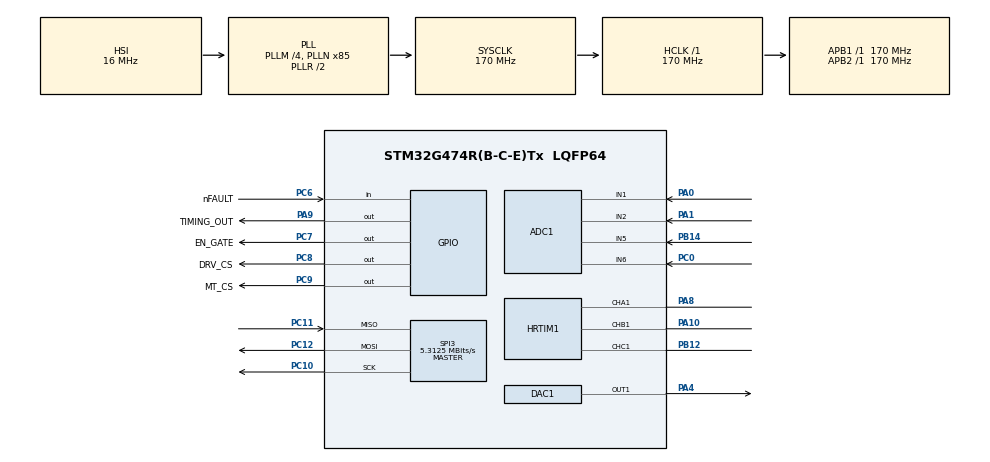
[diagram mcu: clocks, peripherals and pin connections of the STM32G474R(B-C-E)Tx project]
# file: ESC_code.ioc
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ADC1.Channel-0\#ChannelRegularConversion=ADC_CHANNEL_1
ADC1.Channel-1\#ChannelRegularConversion=ADC_CHANNEL_2
ADC1.Channel-2\#ChannelRegularConversion=ADC_CHANNEL_5
ADC1.Channel-3\#ChannelRegularConversion=ADC_CHANNEL_6
ADC1.DMAContinuousRequests=ENABLE
ADC1.ExternalTrigConv=ADC_EXTERNALTRIG_HRTIM_TRG1
ADC1.NbrOfConversion=4
ADC1.NbrOfConversionFlag=1
ADC1.OffsetNumber-0\#ChannelRegularConversion=ADC_OFFSET_NONE
ADC1.OffsetNumber-1\#ChannelRegularConversion=ADC_OFFSET_NONE
ADC1.OffsetNumber-2\#ChannelRegularConversion=ADC_OFFSET_NONE
ADC1.OffsetNumber-3\#ChannelRegularConversion=ADC_OFFSET_NONE
ADC1.Rank-0\#ChannelRegularConversion=1
ADC1.Rank-1\#ChannelRegularConversion=2
ADC1.Rank-2\#ChannelRegularConversion=3
ADC1.Rank-3\#ChannelRegularConversion=4
ADC1.SamplingTime-0\#ChannelRegularConversion=ADC_SAMPLETIME_24CYCLES_5
ADC1.SamplingTime-1\#ChannelRegularConversion=ADC_SAMPLETIME_24CYCLES_5
ADC1.SamplingTime-2\#ChannelRegularConversion=ADC_SAMPLETIME_24CYCLES_5
ADC1.SamplingTime-3\#ChannelRegularConversion=ADC_SAMPLETIME_47CYCLES_5
ADC1.master=1
Dma.ADC1.0.Direction=DMA_PERIPH_TO_MEMORY
Dma.ADC1.0.EventEnable=DISABLE
Dma.ADC1.0.Instance=DMA1_Channel1
Dma.ADC1.0.MemDataAlignment=DMA_MDATAALIGN_HALFWORD
Dma.ADC1.0.MemInc=DMA_MINC_ENABLE
Dma.ADC1.0.Mode=DMA_CIRCULAR
Dma.ADC1.0.PeriphDataAlignment=DMA_PDATAALIGN_HALFWORD
Dma.ADC1.0.PeriphInc=DMA_PINC_DISABLE
Dma.ADC1.0.Polarity=HAL_DMAMUX_REQ_GEN_RISING
Dma.ADC1.0.Priority=DMA_PRIORITY_LOW
Dma.ADC1.0.RequestNumber=1
Dma.ADC1.0.SignalID=NONE
Dma.ADC1.0.SyncEnable=DISABLE
Dma.ADC1.0.SyncPolarity=HAL_DMAMUX_SYNC_NO_EVENT
Dma.ADC1.0.SyncRequestNumber=1
Dma.ADC1.0.SyncSignalID=NONE
Dma.Request0=ADC1
HRTIM1.ADCTrigger1_Source1=HRTIM_ADCTRIGGEREVENT13_MASTER_CMP3
HRTIM1.ADCTrigger_Id1=HRTIM_ADCTRIGGER_1
HRTIM1.CompareUnit1-Output_TA1=HRTIM_COMPAREUNIT_1
HRTIM1.CompareUnit1-Output_TB1=HRTIM_COMPAREUNIT_1
HRTIM1.CompareUnit1-Output_TC1=HRTIM_COMPAREUNIT_1
HRTIM1.CompareUnit2-Output_TA1=HRTIM_COMPAREUNIT_2
HRTIM1.CompareUnit2-Output_TB1=HRTIM_COMPAREUNIT_2
HRTIM1.CompareUnit2-Output_TC1=HRTIM_COMPAREUNIT_2
HRTIM1.CompareUnit3-MasterTimer=HRTIM_COMPAREUNIT_3
HRTIM1.CompareUnit4-MasterTimer=HRTIM_COMPAREUNIT_4
HRTIM1.CompareValue4-MasterTimer=57327
HRTIM1.InterruptRequests1_Master=HRTIM_MASTER_IT_MCMP4
HRTIM1.NumberADCTriggerSource1=1
HRTIM1.NumberInterruptRequests_Master-MasterTimer=1
HRTIM1.NumberResetSource1-Output_TA1=1
HRTIM1.NumberResetSource1-Output_TB1=1
HRTIM1.NumberResetSource1-Output_TC1=1
HRTIM1.NumberSetSource1-Output_TA1=1
HRTIM1.NumberSetSource1-Output_TB1=1
HRTIM1.NumberSetSource1-Output_TC1=1
HRTIM1.ORingUpdateSource_ADCTrigger1=HRTIM_ADCTRIGGERUPDATE_TIMER_A
HRTIM1.PreloadEnable-MasterTimer=HRTIM_PRELOAD_ENABLED
HRTIM1.PreloadEnable-Output_TA1=HRTIM_PRELOAD_DISABLED
HRTIM1.PrescalerRatio_MASTER=HRTIM_PRESCALERRATIO_MUL8
HRTIM1.PrescalerRatio_TA=HRTIM_PRESCALERRATIO_MUL8
HRTIM1.PrescalerRatio_TB=HRTIM_PRESCALERRATIO_MUL8
HRTIM1.PrescalerRatio_TC=HRTIM_PRESCALERRATIO_MUL8
HRTIM1.RepetitionUpdate-MasterTimer=HRTIM_UPDATEONREPETITION_ENABLED
HRTIM1.ResetOutput1_Source1-Output_TA1=HRTIM_OUTPUTRESET_TIMCMP2
HRTIM1.ResetOutput1_Source1-Output_TB1=HRTIM_OUTPUTRESET_TIMCMP2
HRTIM1.ResetOutput1_Source1-Output_TC1=HRTIM_OUTPUTRESET_TIMCMP2
HRTIM1.SetOutput1_Source1-Output_TA1=HRTIM_OUTPUTSET_TIMCMP1
HRTIM1.SetOutput1_Source1-Output_TB1=HRTIM_OUTPUTSET_TIMCMP1
HRTIM1.SetOutput1_Source1-Output_TC1=HRTIM_OUTPUTSET_TIMCMP1
HRTIM1.UpDownMode-Output_TA1=HRTIM_TIMERUPDOWNMODE_UPDOWN
HRTIM1.UpDownMode-Output_TB1=HRTIM_TIMERUPDOWNMODE_UPDOWN
HRTIM1.UpDownMode-Output_TC1=HRTIM_TIMERUPDOWNMODE_UPDOWN
Mcu.Family=STM32G4
Mcu.Name=STM32G474R(B-C-E)Tx
Mcu.Package=LQFP64
NUCLEO-G474RE.BUTTON=1
NUCLEO-G474RE.LD2=true
NUCLEO-G474RE.VCP=true
NVIC.DMA1_Channel1_IRQn=true\:0\:0\:false\:false\:true\:false\:true\:true
NVIC.EXTI15_10_IRQn=true\:0\:0\:false\:false\:true\:false\:true\:true
NVIC.HRTIM1_Master_IRQn=true\:0\:0\:false\:false\:true\:true\:true\:true
NVIC.PriorityGroup=NVIC_PRIORITYGROUP_4
PA0.Mode=IN1-Single-Ended
PA0.Signal=ADC1_IN1
PA1.Mode=IN2-Single-Ended
PA1.Signal=ADC1_IN2
PA10.Mode=Output_TB1
PA10.Signal=HRTIM1_CHB1
PA13.GPIO_Label=T_SWDIO
PA13.Signal=SYS_JTMS-SWDIO
PA14.GPIO_Label=T_SWCLK
PA14.Signal=SYS_JTCK-SWCLK
PA2.Signal=LPUART1_TX
PA3.Signal=LPUART1_RX
PA4.Signal=COMP_DAC11_group
PA8.Mode=Output_TA1
PA8.Signal=HRTIM1_CHA1
PA9.GPIO_Label=TIMING_OUT
PA9.GPIO_Speed=GPIO_SPEED_FREQ_VERY_HIGH
PA9.Signal=GPIO_Output
PB12.Mode=Output_TC1
PB12.Signal=HRTIM1_CHC1
PB14.Mode=IN5-Single-Ended
PB14.Signal=ADC1_IN5
PB3.GPIO_Label=T_SWO
PB3.Signal=SYS_JTDO-SWO
PC0.Mode=IN6-Single-Ended
PC0.Signal=ADC1_IN6
PC10.GPIO_Speed=GPIO_SPEED_FREQ_HIGH
PC10.Mode=Full_Duplex_Master
PC10.Signal=SPI3_SCK
PC11.GPIO_Speed=GPIO_SPEED_FREQ_LOW
PC11.Mode=Full_Duplex_Master
PC11.Signal=SPI3_MISO
PC12.GPIO_Speed=GPIO_SPEED_FREQ_HIGH
PC12.Mode=Full_Duplex_Master
PC12.Signal=SPI3_MOSI
PC14-OSC32_IN.GPIO_Label=RCC_OSC32_IN
PC14-OSC32_IN.Signal=RCC_OSC32_IN
PC15-OSC32_OUT.GPIO_Label=RCC_OSC32_OUT
PC15-OSC32_OUT.Signal=RCC_OSC32_OUT
PC6.GPIO_Label=nFAULT
PC6.GPIO_PuPd=GPIO_PULLUP
PC6.Signal=GPIO_Input
PC7.GPIO_Label=EN_GATE
PC7.GPIO_PuPd=GPIO_NOPULL
PC7.Signal=GPIO_Output
PC8.GPIO_Label=DRV_CS
PC8.GPIO_Speed=GPIO_SPEED_FREQ_HIGH
PC8.PinState=GPIO_PIN_SET
PC8.Signal=GPIO_Output
PC9.GPIO_Label=MT_CS
PC9.GPIO_Speed=GPIO_SPEED_FREQ_HIGH
PC9.PinState=GPIO_PIN_SET
PC9.Signal=GPIO_Output
PF0-OSC_IN.GPIO_Label=RCC_OSC_IN
PF0-OSC_IN.Signal=RCC_OSC_IN
PF1-OSC_OUT.GPIO_Label=RCC_OSC_OUT
PF1-OSC_OUT.Signal=RCC_OSC_OUT
ProjectManager.HeapSize=0x200
ProjectManager.StackSize=0x400
ProjectManager.TargetToolchain=STM32CubeIDE
RCC.ADC12Freq_Value=170000000
RCC.ADC345Freq_Value=170000000
RCC.AHBFreq_Value=170000000
RCC.APB1Freq_Value=170000000
RCC.APB1TimFreq_Value=170000000
RCC.APB2Freq_Value=170000000
RCC.APB2TimFreq_Value=170000000
RCC.CortexFreq_Value=170000000
RCC.EXTERNAL_CLOCK_VALUE=12288000
RCC.HCLKFreq_Value=170000000
RCC.HSE_VALUE=24000000
RCC.HSI48_VALUE=48000000
RCC.HSI_VALUE=16000000
RCC.LSE_VALUE=32768
RCC.PLLM=RCC_PLLM_DIV4
RCC.PLLN=85
RCC.RTCClockSelection=RCC_RTCCLKSOURCE_LSE
RCC.SYSCLKFreq_VALUE=170000000
RCC.SYSCLKSource=RCC_SYSCLKSOURCE_PLLCLK
RCC.USBFreq_Value=170000000
RCC.VCOOutputFreq_Value=340000000
SH.COMP_DAC11_group.0=DAC1_OUT1,DAC_OUT1
SPI3.BaudRatePrescaler=SPI_BAUDRATEPRESCALER_32
SPI3.CLKPhase=SPI_PHASE_2EDGE
SPI3.CalculateBaudRate=5.3125 MBits/s
SPI3.DataSize=SPI_DATASIZE_16BIT
SPI3.Direction=SPI_DIRECTION_2LINES
SPI3.Mode=SPI_MODE_MASTER
SPI3.VirtualType=VM_MASTER
VP_HRTIM1_VS_hrtimMasterTimerNoOutput.Mode=MasterTimer
VP_NUCLEO-G474RE_VS_BSP_COMMON.Mode=COMMON
VP_SYS_VS_DBSignals.Mode=DisableDeadBatterySignals
board=NUCLEO-G474RE

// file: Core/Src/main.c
/* USER CODE BEGIN Header */
/**
  ******************************************************************************
  * @file           : main.c
  * @brief          : Main program body
  ******************************************************************************
  * @attention
  *
  * Copyright (c) 2026 STMicroelectronics.
  * All rights reserved.
  *
  * This software is licensed under terms that can be found in the LICENSE file
  * in the root directory of this software component.
  * If no LICENSE file comes with this software, it is provided AS-IS.
  *
  ******************************************************************************
  */
/* USER CODE END Header */
#include "main.h"

/* USER CODE BEGIN Includes */
#include "drv8305.h"
#include "pwm.h"
#include "board.h"
#include "foc.h"
#include "../../App/bench/bench.h"
/* USER CODE END Includes */

COM_InitTypeDef BspCOMInit;
ADC_HandleTypeDef hadc1;
DMA_HandleTypeDef hdma_adc1;

DAC_HandleTypeDef hdac1;

HRTIM_HandleTypeDef hhrtim1;

SPI_HandleTypeDef hspi3;

/* USER CODE BEGIN PV */
volatile GPIO_PinState nf_low, nf_after, nf_now;   // watch these in Live Expressions
/* USER CODE END PV */

void SystemClock_Config(void);
static void MX_GPIO_Init(void);
static void MX_DMA_Init(void);
static void MX_ADC1_Init(void);
static void MX_HRTIM1_Init(void);
static void MX_DAC1_Init(void);
static void MX_SPI3_Init(void);

int main(void)
{

  /* MCU Configuration--------------------------------------------------------*/

  /* Reset of all peripherals, Initializes the Flash interface and the Systick. */
  HAL_Init();

  /* Configure the system clock */
  SystemClock_Config();

  /* Initialize all configured peripherals */
  MX_GPIO_Init();
  MX_DMA_Init();
  MX_ADC1_Init();
  MX_HRTIM1_Init();
  MX_DAC1_Init();
  MX_SPI3_Init();
  /* USER CODE BEGIN 2 */

  if (!foc_init()) {
    Error_Handler();   /* DRV8305 config or SPI bus bad */
  }
  foc_start();
  /* USER CODE END 2 */

  /* Initialize led */
  BSP_LED_Init(LED_GREEN);

  /* Initialize USER push-button, will be used to trigger an interrupt each time it's pressed.*/
  BSP_PB_Init(BUTTON_USER, BUTTON_MODE_EXTI);

  /* Initialize COM1 port (115200, 8 bits (7-bit data + 1 stop bit), no parity */
  BspCOMInit.BaudRate   = 115200;
  BspCOMInit.WordLength = COM_WORDLENGTH_8B;
  BspCOMInit.StopBits   = COM_STOPBITS_1;
  BspCOMInit.Parity     = COM_PARITY_NONE;
  BspCOMInit.HwFlowCtl  = COM_HWCONTROL_NONE;
  if (BSP_COM_Init(COM1, &BspCOMInit) != BSP_ERROR_NONE)
  {
    Error_Handler();
  }

  /* Infinite loop */
  /* USER CODE BEGIN WHILE */
  bench_init();
  while (1)
  {
    foc_poll();
    bench_poll();
    /* USER CODE END WHILE */

  }
}

void SystemClock_Config(void)
{
  RCC_OscInitTypeDef RCC_OscInitStruct = {0};
  RCC_ClkInitTypeDef RCC_ClkInitStruct = {0};

  /** Configure the main internal regulator output voltage
  */
  HAL_PWREx_ControlVoltageScaling(PWR_REGULATOR_VOLTAGE_SCALE1_BOOST);

  /** Initializes the RCC Oscillators according to the specified parameters
  * in the RCC_OscInitTypeDef structure.
  */
  RCC_OscInitStruct.OscillatorType = RCC_OSCILLATORTYPE_HSI;
  RCC_OscInitStruct.HSIState = RCC_HSI_ON;
  RCC_OscInitStruct.HSICalibrationValue = RCC_HSICALIBRATION_DEFAULT;
  RCC_OscInitStruct.PLL.PLLState = RCC_PLL_ON;
  RCC_OscInitStruct.PLL.PLLSource = RCC_PLLSOURCE_HSI;
  RCC_OscInitStruct.PLL.PLLM = RCC_PLLM_DIV4;
  RCC_OscInitStruct.PLL.PLLN = 85;
  RCC_OscInitStruct.PLL.PLLP = RCC_PLLP_DIV2;
  RCC_OscInitStruct.PLL.PLLQ = RCC_PLLQ_DIV2;
  RCC_OscInitStruct.PLL.PLLR = RCC_PLLR_DIV2;
  if (HAL_RCC_OscConfig(&RCC_OscInitStruct) != HAL_OK)
  {
    Error_Handler();
  }

  /** Initializes the CPU, AHB and APB buses clocks
  */
  RCC_ClkInitStruct.ClockType = RCC_CLOCKTYPE_HCLK|RCC_CLOCKTYPE_SYSCLK
                              |RCC_CLOCKTYPE_PCLK1|RCC_CLOCKTYPE_PCLK2;
  RCC_ClkInitStruct.SYSCLKSource = RCC_SYSCLKSOURCE_PLLCLK;
  RCC_ClkInitStruct.AHBCLKDivider = RCC_SYSCLK_DIV1;
  RCC_ClkInitStruct.APB1CLKDivider = RCC_HCLK_DIV1;
  RCC_ClkInitStruct.APB2CLKDivider = RCC_HCLK_DIV1;

  if (HAL_RCC_ClockConfig(&RCC_ClkInitStruct, FLASH_LATENCY_4) != HAL_OK)
  {
    Error_Handler();
  }
}

static void MX_ADC1_Init(void)
{

  ADC_MultiModeTypeDef multimode = {0};
  ADC_ChannelConfTypeDef sConfig = {0};

  /** Common config
  */
  hadc1.Instance = ADC1;
  hadc1.Init.ClockPrescaler = ADC_CLOCK_SYNC_PCLK_DIV4;
  hadc1.Init.Resolution = ADC_RESOLUTION_12B;
  hadc1.Init.DataAlign = ADC_DATAALIGN_RIGHT;
  hadc1.Init.GainCompensation = 0;
  hadc1.Init.ScanConvMode = ADC_SCAN_ENABLE;
  hadc1.Init.EOCSelection = ADC_EOC_SINGLE_CONV;
  hadc1.Init.LowPowerAutoWait = DISABLE;
  hadc1.Init.ContinuousConvMode = DISABLE;
  hadc1.Init.NbrOfConversion = 4;
  hadc1.Init.DiscontinuousConvMode = DISABLE;
  hadc1.Init.ExternalTrigConv = ADC_EXTERNALTRIG_HRTIM_TRG1;
  hadc1.Init.ExternalTrigConvEdge = ADC_EXTERNALTRIGCONVEDGE_RISING;
  hadc1.Init.DMAContinuousRequests = ENABLE;
  hadc1.Init.Overrun = ADC_OVR_DATA_PRESERVED;
  hadc1.Init.OversamplingMode = DISABLE;
  if (HAL_ADC_Init(&hadc1) != HAL_OK)
  {
    Error_Handler();
  }

  /** Configure the ADC multi-mode
  */
  multimode.Mode = ADC_MODE_INDEPENDENT;
  if (HAL_ADCEx_MultiModeConfigChannel(&hadc1, &multimode) != HAL_OK)
  {
    Error_Handler();
  }

  /** Configure Regular Channel
  */
  sConfig.Channel = ADC_CHANNEL_1;
  sConfig.Rank = ADC_REGULAR_RANK_1;
  sConfig.SamplingTime = ADC_SAMPLETIME_24CYCLES_5;
  sConfig.SingleDiff = ADC_SINGLE_ENDED;
  sConfig.OffsetNumber = ADC_OFFSET_NONE;
  sConfig.Offset = 0;
  if (HAL_ADC_ConfigChannel(&hadc1, &sConfig) != HAL_OK)
  {
    Error_Handler();
  }

  /** Configure Regular Channel
  */
  sConfig.Channel = ADC_CHANNEL_2;
  sConfig.Rank = ADC_REGULAR_RANK_2;
  if (HAL_ADC_ConfigChannel(&hadc1, &sConfig) != HAL_OK)
  {
    Error_Handler();
  }

  /** Configure Regular Channel
  */
  sConfig.Channel = ADC_CHANNEL_5;
  sConfig.Rank = ADC_REGULAR_RANK_3;
  if (HAL_ADC_ConfigChannel(&hadc1, &sConfig) != HAL_OK)
  {
    Error_Handler();
  }

  /** Configure Regular Channel
  */
  sConfig.Channel = ADC_CHANNEL_6;
  sConfig.Rank = ADC_REGULAR_RANK_4;
  sConfig.SamplingTime = ADC_SAMPLETIME_47CYCLES_5;
  if (HAL_ADC_ConfigChannel(&hadc1, &sConfig) != HAL_OK)
  {
    Error_Handler();
  }

}

static void MX_DAC1_Init(void)
{

  DAC_ChannelConfTypeDef sConfig = {0};

  /** DAC Initialization
  */
  hdac1.Instance = DAC1;
  if (HAL_DAC_Init(&hdac1) != HAL_OK)
  {
    Error_Handler();
  }

  /** DAC channel OUT1 config
  */
  sConfig.DAC_HighFrequency = DAC_HIGH_FREQUENCY_INTERFACE_MODE_AUTOMATIC;
  sConfig.DAC_DMADoubleDataMode = DISABLE;
  sConfig.DAC_SignedFormat = DISABLE;
  sConfig.DAC_SampleAndHold = DAC_SAMPLEANDHOLD_DISABLE;
  sConfig.DAC_Trigger = DAC_TRIGGER_NONE;
  sConfig.DAC_Trigger2 = DAC_TRIGGER_NONE;
  sConfig.DAC_OutputBuffer = DAC_OUTPUTBUFFER_ENABLE;
  sConfig.DAC_ConnectOnChipPeripheral = DAC_CHIPCONNECT_EXTERNAL;
  sConfig.DAC_UserTrimming = DAC_TRIMMING_FACTORY;
  if (HAL_DAC_ConfigChannel(&hdac1, &sConfig, DAC_CHANNEL_1) != HAL_OK)
  {
    Error_Handler();
  }

}

static void MX_HRTIM1_Init(void)
{

  HRTIM_ADCTriggerCfgTypeDef pADCTriggerCfg = {0};
  HRTIM_TimeBaseCfgTypeDef pTimeBaseCfg = {0};
  HRTIM_TimerCfgTypeDef pTimerCfg = {0};
  HRTIM_CompareCfgTypeDef pCompareCfg = {0};
  HRTIM_TimerCtlTypeDef pTimerCtl = {0};
  HRTIM_OutputCfgTypeDef pOutputCfg = {0};

  hhrtim1.Instance = HRTIM1;
  hhrtim1.Init.HRTIMInterruptResquests = HRTIM_IT_NONE;
  hhrtim1.Init.SyncOptions = HRTIM_SYNCOPTION_NONE;
  if (HAL_HRTIM_Init(&hhrtim1) != HAL_OK)
  {
    Error_Handler();
  }
  if (HAL_HRTIM_DLLCalibrationStart(&hhrtim1, HRTIM_CALIBRATIONRATE_3) != HAL_OK)
  {
    Error_Handler();
  }
  if (HAL_HRTIM_PollForDLLCalibration(&hhrtim1, 10) != HAL_OK)
  {
    Error_Handler();
  }
  pADCTriggerCfg.UpdateSource = HRTIM_ADCTRIGGERUPDATE_TIMER_A;
  pADCTriggerCfg.Trigger = HRTIM_ADCTRIGGEREVENT13_MASTER_CMP3;
  if (HAL_HRTIM_ADCTriggerConfig(&hhrtim1, HRTIM_ADCTRIGGER_1, &pADCTriggerCfg) != HAL_OK)
  {
    Error_Handler();
  }
  if (HAL_HRTIM_ADCPostScalerConfig(&hhrtim1, HRTIM_ADCTRIGGER_1, 0x0) != HAL_OK)
  {
    Error_Handler();
  }
  pTimeBaseCfg.Period = 0xFFF7;
  pTimeBaseCfg.RepetitionCounter = 0x00;
  pTimeBaseCfg.PrescalerRatio = HRTIM_PRESCALERRATIO_MUL8;
  pTimeBaseCfg.Mode = HRTIM_MODE_CONTINUOUS;
  if (HAL_HRTIM_TimeBaseConfig(&hhrtim1, HRTIM_TIMERINDEX_MASTER, &pTimeBaseCfg) != HAL_OK)
  {
    Error_Handler();
  }
  pTimerCfg.InterruptRequests = HRTIM_MASTER_IT_MCMP4;
  pTimerCfg.DMARequests = HRTIM_MASTER_DMA_NONE;
  pTimerCfg.DMASrcAddress = 0x0000;
  pTimerCfg.DMADstAddress = 0x0000;
  pTimerCfg.DMASize = 0x1;
  pTimerCfg.HalfModeEnable = HRTIM_HALFMODE_DISABLED;
  pTimerCfg.InterleavedMode = HRTIM_INTERLEAVED_MODE_DISABLED;
  pTimerCfg.StartOnSync = HRTIM_SYNCSTART_DISABLED;
  pTimerCfg.ResetOnSync = HRTIM_SYNCRESET_DISABLED;
  pTimerCfg.DACSynchro = HRTIM_DACSYNC_NONE;
  pTimerCfg.PreloadEnable = HRTIM_PRELOAD_ENABLED;
  pTimerCfg.UpdateGating = HRTIM_UPDATEGATING_INDEPENDENT;
  pTimerCfg.BurstMode = HRTIM_TIMERBURSTMODE_MAINTAINCLOCK;
  pTimerCfg.RepetitionUpdate = HRTIM_UPDATEONREPETITION_ENABLED;
  pTimerCfg.ReSyncUpdate = HRTIM_TIMERESYNC_UPDATE_UNCONDITIONAL;
  if (HAL_HRTIM_WaveformTimerConfig(&hhrtim1, HRTIM_TIMERINDEX_MASTER, &pTimerCfg) != HAL_OK)
  {
    Error_Handler();
  }
  pCompareCfg.CompareValue = 0xFFF7;
  if (HAL_HRTIM_WaveformCompareConfig(&hhrtim1, HRTIM_TIMERINDEX_MASTER, HRTIM_COMPAREUNIT_3, &pCompareCfg) != HAL_OK)
  {
    Error_Handler();
  }
  pCompareCfg.CompareValue = 57327;
  if (HAL_HRTIM_WaveformCompareConfig(&hhrtim1, HRTIM_TIMERINDEX_MASTER, HRTIM_COMPAREUNIT_4, &pCompareCfg) != HAL_OK)
  {
    Error_Handler();
  }
  if (HAL_HRTIM_TimeBaseConfig(&hhrtim1, HRTIM_TIMERINDEX_TIMER_A, &pTimeBaseCfg) != HAL_OK)
  {
    Error_Handler();
  }
  pTimerCtl.UpDownMode = HRTIM_TIMERUPDOWNMODE_UPDOWN;
  pTimerCtl.TrigHalf = HRTIM_TIMERTRIGHALF_DISABLED;
  pTimerCtl.GreaterCMP1 = HRTIM_TIMERGTCMP1_EQUAL;
  pTimerCtl.DualChannelDacEnable = HRTIM_TIMER_DCDE_DISABLED;
  if (HAL_HRTIM_WaveformTimerControl(&hhrtim1, HRTIM_TIMERINDEX_TIMER_A, &pTimerCtl) != HAL_OK)
  {
    Error_Handler();
  }
  if (HAL_HRTIM_RollOverModeConfig(&hhrtim1, HRTIM_TIMERINDEX_TIMER_A, HRTIM_TIM_FEROM_BOTH|HRTIM_TIM_BMROM_BOTH
                              |HRTIM_TIM_ADROM_BOTH|HRTIM_TIM_OUTROM_BOTH
                              |HRTIM_TIM_ROM_BOTH) != HAL_OK)
  {
    Error_Handler();
  }
  pTimerCfg.InterruptRequests = HRTIM_TIM_IT_NONE;
  pTimerCfg.DMARequests = HRTIM_TIM_DMA_NONE;
  pTimerCfg.PreloadEnable = HRTIM_PRELOAD_DISABLED;
  pTimerCfg.RepetitionUpdate = HRTIM_UPDATEONREPETITION_DISABLED;
  pTimerCfg.PushPull = HRTIM_TIMPUSHPULLMODE_DISABLED;
  pTimerCfg.FaultEnable = HRTIM_TIMFAULTENABLE_NONE;
  pTimerCfg.FaultLock = HRTIM_TIMFAULTLOCK_READWRITE;
  pTimerCfg.DeadTimeInsertion = HRTIM_TIMDEADTIMEINSERTION_DISABLED;
  pTimerCfg.DelayedProtectionMode = HRTIM_TIMER_A_B_C_DELAYEDPROTECTION_DISABLED;
  pTimerCfg.UpdateTrigger = HRTIM_TIMUPDATETRIGGER_NONE;
  pTimerCfg.ResetTrigger = HRTIM_TIMRESETTRIGGER_NONE;
  pTimerCfg.ResetUpdate = HRTIM_TIMUPDATEONRESET_DISABLED;
  if (HAL_HRTIM_WaveformTimerConfig(&hhrtim1, HRTIM_TIMERINDEX_TIMER_A, &pTimerCfg) != HAL_OK)
  {
    Error_Handler();
  }
  if (HAL_HRTIM_WaveformTimerConfig(&hhrtim1, HRTIM_TIMERINDEX_TIMER_B, &pTimerCfg) != HAL_OK)
  {
    Error_Handler();
  }
  if (HAL_HRTIM_WaveformTimerConfig(&hhrtim1, HRTIM_TIMERINDEX_TIMER_C, &pTimerCfg) != HAL_OK)
  {
    Error_Handler();
  }
  pCompareCfg.CompareValue = 0xFFF7;
  if (HAL_HRTIM_WaveformCompareConfig(&hhrtim1, HRTIM_TIMERINDEX_TIMER_A, HRTIM_COMPAREUNIT_1, &pCompareCfg) != HAL_OK)
  {
    Error_Handler();
  }
  pCompareCfg.AutoDelayedMode = HRTIM_AUTODELAYEDMODE_REGULAR;
  pCompareCfg.AutoDelayedTimeout = 0x0000;

  if (HAL_HRTIM_WaveformCompareConfig(&hhrtim1, HRTIM_TIMERINDEX_TIMER_A, HRTIM_COMPAREUNIT_2, &pCompareCfg) != HAL_OK)
  {
    Error_Handler();
  }
  pOutputCfg.Polarity = HRTIM_OUTPUTPOLARITY_HIGH;
  pOutputCfg.SetSource = HRTIM_OUTPUTSET_TIMCMP1;
  pOutputCfg.ResetSource = HRTIM_OUTPUTRESET_TIMCMP2;
  pOutputCfg.IdleMode = HRTIM_OUTPUTIDLEMODE_NONE;
  pOutputCfg.IdleLevel = HRTIM_OUTPUTIDLELEVEL_INACTIVE;
  pOutputCfg.FaultLevel = HRTIM_OUTPUTFAULTLEVEL_NONE;
  pOutputCfg.ChopperModeEnable = HRTIM_OUTPUTCHOPPERMODE_DISABLED;
  pOutputCfg.BurstModeEntryDelayed = HRTIM_OUTPUTBURSTMODEENTRY_REGULAR;
  if (HAL_HRTIM_WaveformOutputConfig(&hhrtim1, HRTIM_TIMERINDEX_TIMER_A, HRTIM_OUTPUT_TA1, &pOutputCfg) != HAL_OK)
  {
    Error_Handler();
  }
  if (HAL_HRTIM_WaveformOutputConfig(&hhrtim1, HRTIM_TIMERINDEX_TIMER_B, HRTIM_OUTPUT_TB1, &pOutputCfg) != HAL_OK)
  {
    Error_Handler();
  }
  if (HAL_HRTIM_WaveformOutputConfig(&hhrtim1, HRTIM_TIMERINDEX_TIMER_C, HRTIM_OUTPUT_TC1, &pOutputCfg) != HAL_OK)
  {
    Error_Handler();
  }
  if (HAL_HRTIM_TimeBaseConfig(&hhrtim1, HRTIM_TIMERINDEX_TIMER_B, &pTimeBaseCfg) != HAL_OK)
  {
    Error_Handler();
  }
  if (HAL_HRTIM_WaveformTimerControl(&hhrtim1, HRTIM_TIMERINDEX_TIMER_B, &pTimerCtl) != HAL_OK)
  {
    Error_Handler();
  }
  if (HAL_HRTIM_RollOverModeConfig(&hhrtim1, HRTIM_TIMERINDEX_TIMER_B, HRTIM_TIM_FEROM_BOTH|HRTIM_TIM_BMROM_BOTH
                              |HRTIM_TIM_ADROM_BOTH|HRTIM_TIM_OUTROM_BOTH
                              |HRTIM_TIM_ROM_BOTH) != HAL_OK)
  {
    Error_Handler();
  }
  if (HAL_HRTIM_WaveformCompareConfig(&hhrtim1, HRTIM_TIMERINDEX_TIMER_B, HRTIM_COMPAREUNIT_1, &pCompareCfg) != HAL_OK)
  {
    Error_Handler();
  }

  if (HAL_HRTIM_WaveformCompareConfig(&hhrtim1, HRTIM_TIMERINDEX_TIMER_B, HRTIM_COMPAREUNIT_2, &pCompareCfg) != HAL_OK)
  {
    Error_Handler();
  }
  if (HAL_HRTIM_TimeBaseConfig(&hhrtim1, HRTIM_TIMERINDEX_TIMER_C, &pTimeBaseCfg) != HAL_OK)
  {
    Error_Handler();
  }
  if (HAL_HRTIM_WaveformTimerControl(&hhrtim1, HRTIM_TIMERINDEX_TIMER_C, &pTimerCtl) != HAL_OK)
  {
    Error_Handler();
  }
  if (HAL_HRTIM_RollOverModeConfig(&hhrtim1, HRTIM_TIMERINDEX_TIMER_C, HRTIM_TIM_FEROM_BOTH|HRTIM_TIM_BMROM_BOTH
                              |HRTIM_TIM_ADROM_BOTH|HRTIM_TIM_OUTROM_BOTH
                              |HRTIM_TIM_ROM_BOTH) != HAL_OK)
  {
    Error_Handler();
  }
  if (HAL_HRTIM_WaveformCompareConfig(&hhrtim1, HRTIM_TIMERINDEX_TIMER_C, HRTIM_COMPAREUNIT_1, &pCompareCfg) != HAL_OK)
  {
    Error_Handler();
  }

  if (HAL_HRTIM_WaveformCompareConfig(&hhrtim1, HRTIM_TIMERINDEX_TIMER_C, HRTIM_COMPAREUNIT_2, &pCompareCfg) != HAL_OK)
  {
    Error_Handler();
  }
  HAL_HRTIM_MspPostInit(&hhrtim1);

}

static void MX_SPI3_Init(void)
{

  /* SPI3 parameter configuration*/
  hspi3.Instance = SPI3;
  hspi3.Init.Mode = SPI_MODE_MASTER;
  hspi3.Init.Direction = SPI_DIRECTION_2LINES;
  hspi3.Init.DataSize = SPI_DATASIZE_16BIT;
  hspi3.Init.CLKPolarity = SPI_POLARITY_LOW;
  hspi3.Init.CLKPhase = SPI_PHASE_2EDGE;
  hspi3.Init.NSS = SPI_NSS_SOFT;
  hspi3.Init.BaudRatePrescaler = SPI_BAUDRATEPRESCALER_32;
  hspi3.Init.FirstBit = SPI_FIRSTBIT_MSB;
  hspi3.Init.TIMode = SPI_TIMODE_DISABLE;
  hspi3.Init.CRCCalculation = SPI_CRCCALCULATION_DISABLE;
  hspi3.Init.CRCPolynomial = 7;
  hspi3.Init.CRCLength = SPI_CRC_LENGTH_DATASIZE;
  hspi3.Init.NSSPMode = SPI_NSS_PULSE_DISABLE;
  if (HAL_SPI_Init(&hspi3) != HAL_OK)
  {
    Error_Handler();
  }

}

static void MX_DMA_Init(void)
{

  /* DMA controller clock enable */
  __HAL_RCC_DMAMUX1_CLK_ENABLE();
  __HAL_RCC_DMA1_CLK_ENABLE();

  /* DMA interrupt init */
  /* DMA1_Channel1_IRQn interrupt configuration */
  HAL_NVIC_SetPriority(DMA1_Channel1_IRQn, 0, 0);
  HAL_NVIC_EnableIRQ(DMA1_Channel1_IRQn);

}

static void MX_GPIO_Init(void)
{
  GPIO_InitTypeDef GPIO_InitStruct = {0};

  /* GPIO Ports Clock Enable */
  __HAL_RCC_GPIOC_CLK_ENABLE();
  __HAL_RCC_GPIOF_CLK_ENABLE();
  __HAL_RCC_GPIOA_CLK_ENABLE();
  __HAL_RCC_GPIOB_CLK_ENABLE();

  /*Configure GPIO pin Output Level */
  HAL_GPIO_WritePin(EN_GATE_GPIO_Port, EN_GATE_Pin, GPIO_PIN_RESET);

  /*Configure GPIO pin Output Level */
  HAL_GPIO_WritePin(GPIOC, DRV_CS_Pin|MT_CS_Pin, GPIO_PIN_SET);

  /*Configure GPIO pin Output Level */
  HAL_GPIO_WritePin(TIMING_OUT_GPIO_Port, TIMING_OUT_Pin, GPIO_PIN_RESET);

  /*Configure GPIO pin : nFAULT_Pin */
  GPIO_InitStruct.Pin = nFAULT_Pin;
  GPIO_InitStruct.Mode = GPIO_MODE_INPUT;
  GPIO_InitStruct.Pull = GPIO_PULLUP;
  HAL_GPIO_Init(nFAULT_GPIO_Port, &GPIO_InitStruct);

  /*Configure GPIO pin : EN_GATE_Pin */
  GPIO_InitStruct.Pin = EN_GATE_Pin;
  GPIO_InitStruct.Mode = GPIO_MODE_OUTPUT_PP;
  GPIO_InitStruct.Pull = GPIO_NOPULL;
  GPIO_InitStruct.Speed = GPIO_SPEED_FREQ_LOW;
  HAL_GPIO_Init(EN_GATE_GPIO_Port, &GPIO_InitStruct);

  /*Configure GPIO pins : DRV_CS_Pin MT_CS_Pin */
  GPIO_InitStruct.Pin = DRV_CS_Pin|MT_CS_Pin;
  GPIO_InitStruct.Mode = GPIO_MODE_OUTPUT_PP;
  GPIO_InitStruct.Pull = GPIO_NOPULL;
  GPIO_InitStruct.Speed = GPIO_SPEED_FREQ_HIGH;
  HAL_GPIO_Init(GPIOC, &GPIO_InitStruct);

  /*Configure GPIO pin : TIMING_OUT_Pin */
  GPIO_InitStruct.Pin = TIMING_OUT_Pin;
  GPIO_InitStruct.Mode = GPIO_MODE_OUTPUT_PP;
  GPIO_InitStruct.Pull = GPIO_NOPULL;
  GPIO_InitStruct.Speed = GPIO_SPEED_FREQ_VERY_HIGH;
  HAL_GPIO_Init(TIMING_OUT_GPIO_Port, &GPIO_InitStruct);

}

void Error_Handler(void)
{
  __disable_irq();
  while (1)
  {
  }
}
